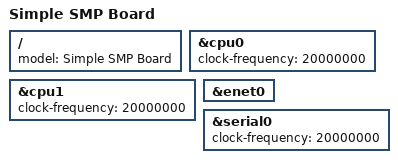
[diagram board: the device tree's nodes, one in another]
// SPDX-License-Identifier: GPL-2.0

/dts-v1/;

#include "simple-smp.dtsi"

/ {
	model = "Simple SMP Board";
};

&cpu0 {
	clock-frequency = <20000000>;
};

&cpu1 {
	clock-frequency = <20000000>;
};

&enet0 {
	status = "okay";
};

&serial0 {
	clock-frequency = <20000000>;
};
